# MDR1986VK214 register map
Vendor: Milandr; Series: ARMCM0; File version: 2.0
CPU: CM0 r0p0, little endian, no MPU, no FPU, 2 interrupt priority bits
Registers are 32-bit, read-write, reset 0x0 unless marked. A register's access mark holds for its fields unless they carry their own. Offsets are from the block's base; [hi:lo] are bit positions; {n}, {i} and the like mark numbered series.

## MDR_ADC — Successive Approximation ADC
Base 0x40040000
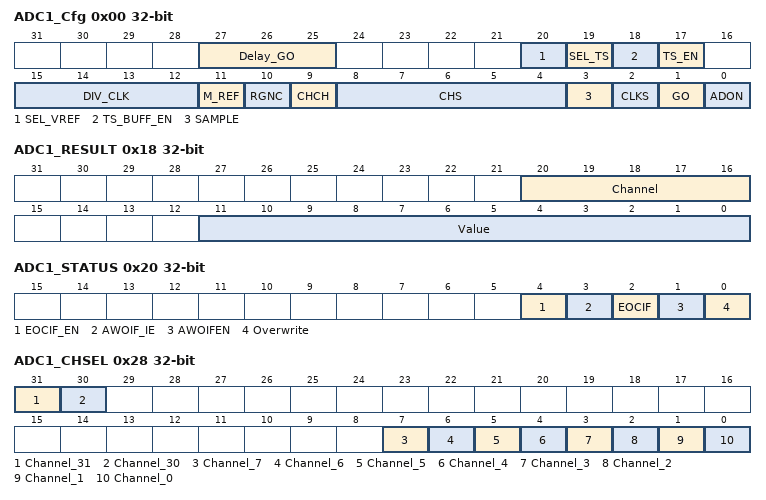
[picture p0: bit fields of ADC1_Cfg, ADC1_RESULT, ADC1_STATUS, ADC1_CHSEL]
0x00 ADC1_Cfg — ADC1 config register
  [27:25] Delay_GO — Delay after channels switching in CPU_CLK
    0=1 period of CPU_CLK; {v}={v+1} periods of CPU_CLK (v=1..7)
  [20] SEL_VREF — Output Vref=1.23 from Thermosensor
    0=Disable (Channel 30 signal is undefined); 1=Selected (Channel 30 signal is VRef)
  [19] SEL_TS — Output temperature from Thermosensor
    0=Disable (Channel 31 signal is undefined); 1=Selected (Channel 31 signal is temperature)
  [18] TS_BUFF_EN — Thermosensor buffer enable
    0=Disable (Thermosensor buffer disabled); 1=Enable (Thermosensor buffer enabled)
  [17] TS_EN — Thermosensor enable
    0=Disable (Thermosensor power off); 1=Enable (Thermosensor power on)
  [15:12] DIV_CLK — Divider for CPU_Clock usage
    0=div_1 (CLK = CPU_CLK); 1=div_2 (CLK = CPU_CLK/2); 2=div_4 (CLK = CPU_CLK/4); 3=div_8 (CLK = CPU_CLK/8); 4=div_16 (CLK = CPU_CLK/16); 5=div_32 (CLK = CPU_CLK/32); 6=div_64 (CLK = CPU_CLK/64); 7=div_128 (CLK = CPU_CLK/128); 8=div_256 (CLK = CPU_CLK/256); 9=div_512 (CLK = CPU_CLK/512); 10=div_1024 (CLK = CPU_CLK/1024); 11=div_2048 (CLK = CPU_CLK/2048)
  [11] M_REF — Signal amplitude reference
    0=Internal (Signal in [GND..AUcc]); 1=External (Signal in [ADC_Ref-..ADC_Ref+])
  [10] RGNC — Signal limiters enable
    0=Disable (Flag STATUSx.AWOIFEN inactive); 1=Enable (Flag STATUSx.AWOIFEN enable)
  [9] CHCH — Channel switching enable
    0=Disable (Measure only CHS channel); 1=Enable (Measure channels selected in reg CHSEL)
  [8:4] CHS — Active channel select
    0=Channel_0_RefN (Signal on PC4, Ref-); 1=Channel_1_RefP (Signal on PC3, Ref+); 2=Channel_2 (Signal on PC2); 3=Channel_3 (Signal on PC1); 4=Channel_4 (Signal on PB9); 5=Channel_5 (Signal on PB8); 6=Channel_6 (Signal on PB7); 7=Channel_7 (Signal on PB6); 30=TS_VRef_1.23 (Signal from Thermosensor); 31=TS_Temperature (Signal from Thermosensor)
  [3] SAMPLE — Single or Continuous measurement
    0=Single measurement by GO; 1=Continuouse (Continuous measurement, until stop by ADON)
  [2] CLKS — Select Clock
    0=CPU_Clock used; 1=ADC_Clock used
  [1] GO — Start single ADC mesurement
    0=Inactive (Autoclear to zero after start); 1=Start measurement
  [0] ADON — Enable ADC
    0=Off (Disabled); 1=On (Enabled)
0x04 ADC2_Cfg — ADC2 config register
  [17] ADC1_OP — ADC1 Setpoint Vref source
    0=Own (Own setpoint Vref); 1=Thermosensor (Setpoint Vref from Thermosensor)
0x08 ADC1_H_Level — ADC High limit
  [11:0] Level — Signal limit level
0x10 ADC1_L_Level — ADC Low limit
  [11:0] Level — Signal limit level
0x18 ADC1_RESULT ro (reset mask 0xF0FFF) — ADC result register
  [20:16] Channel — Channel index
    0=Channel_0_RefN (Signal on PC4, Ref-); 1=Channel_1_RefP (Signal on PC3, Ref+); 2=Signal on PC2; 3=Signal on PC1; 4=Signal on PB9; 5=Signal on PB8; 6=Signal on PB7; 7=Signal on PB6; 30=TS_VRef_1.23 (Signal from Thermosensor); 31=TS_Temperature (Signal from Thermosensor)
  [11:0] Value — Channel signal value
0x20 ADC1_STATUS — ADC status register
  [4] EOCIF_EN — Enable IRQ by EOCIF flag
    0=Disable (IRQ Disable); 1=Enable (IRQ Enable)
  [3] AWOIF_IE — Enable IRQ by AWOIFEN flag
    0=Disable (IRQ Disable); 1=Enable (IRQ Enable)
  [2] EOCIF — Result ready to read
    0=NoResult (Result is not ready); 1=Ready (Signal is ready to read)
  [1] AWOIFEN — Signal is out of limiters range
    0=InRange (Signal in range); 1=OutOfRange (Signal is out of range)
  [0] Overwrite — Result overwritten flag
    0=Normal (No overwritten occure); 1=Overwrite (Result overwritten)
0x28 ADC1_CHSEL — ADC channels select register
  [all] fields
    0=Off (Not used in channels switching); 1=Selected (Using in channels switching)
  [31] Channel_31 — Temperature from Thermosensor
  [30] Channel_30 — VRef from Thermosensor
  [7] Channel_7 — Signal on PB6
  [6] Channel_6 — Signal on PB7
  [5] Channel_5 — Signal on PB8
  [4] Channel_4 — Signal on PB9
  [3] Channel_3 — Signal on PC1
  [2] Channel_2 — Signal on PC2
  [1] Channel_1 — Signal on PC3, Ref+
  [0] Channel_0 — Signal on PC4, Ref-
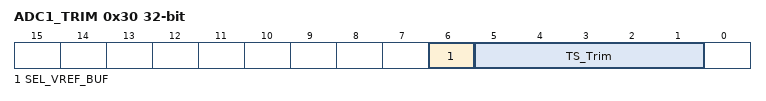
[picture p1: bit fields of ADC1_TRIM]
0x30 ADC1_TRIM (reset mask 0x1E) — ADC TS_Vref trim register
  [6] SEL_VREF_BUF — Output Vref_Buf=1.23 from Thermosensor
    0=Disable (Channel 30 signal is undefined); 1=Selected (Channel 30 signal is VRef_Buf)
  [5:1] TS_Trim — Trim Vref from Thermosensor
    0=Vref_1v23 (1.23V typically); 1=Vref_1v213 (1.213V typically); 2=Vref_1v211 (1.211V typically); 3=Vref_1v208 (1.208V typically); 4=Vref_1v206 (1.206V typically); 5=Vref_1v203 (1.203V typically); 6=Vref_1v200 (1.200V typically); 7=Vref_1v197 (1.197V typically); 8=Vref_1v193 (1.193V typically)
